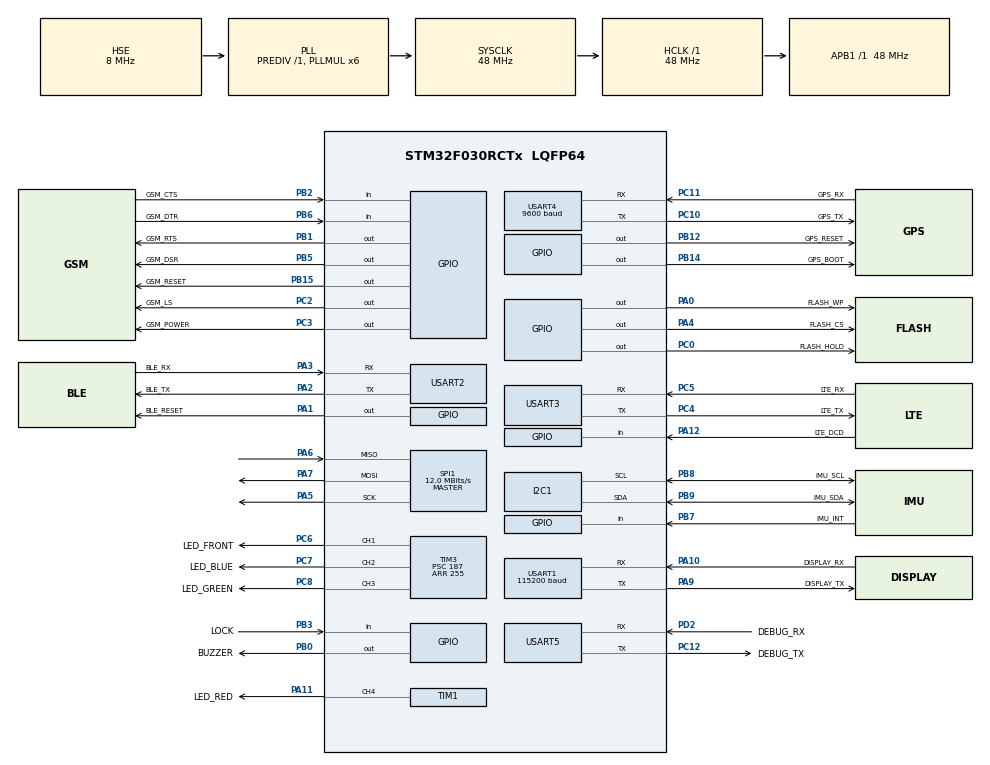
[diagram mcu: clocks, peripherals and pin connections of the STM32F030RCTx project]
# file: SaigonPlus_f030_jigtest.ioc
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Dma.Request0=USART2_RX
Dma.Request1=USART3_RX
Dma.Request2=USART4_RX
Dma.USART2_RX.0.Direction=DMA_PERIPH_TO_MEMORY
Dma.USART2_RX.0.Instance=DMA1_Channel5
Dma.USART2_RX.0.MemDataAlignment=DMA_MDATAALIGN_BYTE
Dma.USART2_RX.0.MemInc=DMA_MINC_ENABLE
Dma.USART2_RX.0.Mode=DMA_NORMAL
Dma.USART2_RX.0.PeriphDataAlignment=DMA_PDATAALIGN_BYTE
Dma.USART2_RX.0.PeriphInc=DMA_PINC_DISABLE
Dma.USART2_RX.0.Priority=DMA_PRIORITY_LOW
Dma.USART3_RX.1.Direction=DMA_PERIPH_TO_MEMORY
Dma.USART3_RX.1.Instance=DMA1_Channel1
Dma.USART3_RX.1.MemDataAlignment=DMA_MDATAALIGN_BYTE
Dma.USART3_RX.1.MemInc=DMA_MINC_ENABLE
Dma.USART3_RX.1.Mode=DMA_NORMAL
Dma.USART3_RX.1.PeriphDataAlignment=DMA_PDATAALIGN_BYTE
Dma.USART3_RX.1.PeriphInc=DMA_PINC_DISABLE
Dma.USART3_RX.1.Priority=DMA_PRIORITY_LOW
Dma.USART4_RX.2.Direction=DMA_PERIPH_TO_MEMORY
Dma.USART4_RX.2.Instance=DMA1_Channel3
Dma.USART4_RX.2.MemDataAlignment=DMA_MDATAALIGN_BYTE
Dma.USART4_RX.2.MemInc=DMA_MINC_ENABLE
Dma.USART4_RX.2.Mode=DMA_NORMAL
Dma.USART4_RX.2.PeriphDataAlignment=DMA_PDATAALIGN_BYTE
Dma.USART4_RX.2.PeriphInc=DMA_PINC_DISABLE
Dma.USART4_RX.2.Priority=DMA_PRIORITY_LOW
FREERTOS.INCLUDE_uxTaskGetStackHighWaterMark=1
FREERTOS.Mutexes01=appResource,Static,appResourceControlBlock;debugMutex,Static,debugMutexControlBlock;buzzerMutex,Static,buzzerMutexControlBlock;flashMutex,Static,flashMutexControlBlock;lteRingbufMutex,Static,lteRingbufMutexControlBlock;jigtestMutex,Static,jigtestMutexControlBlock
FREERTOS.Queues01=mainMail,5,mail_t,0,Static,mainMailBuffer,mainMailControlBlock;lteMail,5,mail_t,0,Static,lteMailBuffer,lteMailControlBlock;mqttMail,5,mail_t,0,Static,mqttMailBuffer,mqttMailControlBlock;jigTestMail,5,jigtest_mail_t,0,Static,jigTestMailBuffer,jigTestMailControlBlock
FREERTOS.Tasks01=mainTask,24,512,StartMainTask,Default,NULL,Static,mainTaskBuffer,mainTaskControlBlock;lteTask,24,512,LteTaskStart,Default,NULL,Static,lteTaskBuffer,lteTaskControlBlock;mqttTask,24,512,MqttTaskStart,Default,NULL,Static,mqttTaskBuffer,mqttTaskControlBlock;jigtestTask,24,256,StartJigtestTask,Default,NULL,Static,jigtestTaskBuffer,jigtestTaskControlBlock
FREERTOS.configTOTAL_HEAP_SIZE=1024
FREERTOS.configUSE_NEWLIB_REENTRANT=1
FREERTOS.configUSE_TIMERS=1
IWDG.Prescaler=IWDG_PRESCALER_256
Mcu.Family=STM32F0
Mcu.Name=STM32F030RCTx
Mcu.Package=LQFP64
NVIC.DMA1_Channel1_IRQn=true\:3\:0\:false\:false\:true\:true\:false\:true
NVIC.DMA1_Channel2_3_IRQn=true\:3\:0\:false\:false\:true\:true\:false\:true
NVIC.DMA1_Channel4_5_IRQn=true\:3\:0\:false\:false\:true\:true\:false\:true
NVIC.I2C1_IRQn=true\:3\:0\:true\:false\:true\:true\:true\:true
NVIC.TIM17_IRQn=true\:0\:0\:false\:false\:true\:false\:false\:true
NVIC.TimeBase=TIM17_IRQn
NVIC.TimeBaseIP=TIM17
NVIC.USART1_IRQn=true\:3\:0\:false\:false\:true\:true\:true\:true
NVIC.USART2_IRQn=true\:3\:0\:false\:false\:true\:true\:true\:true
NVIC.USART3_6_IRQn=true\:3\:0\:false\:false\:true\:true\:true\:true
PA0.GPIO_Label=FLASH_WP
PA0.PinState=GPIO_PIN_SET
PA0.Signal=GPIO_Output
PA1.GPIO_Label=BLE_RESET
PA1.PinState=GPIO_PIN_SET
PA1.Signal=GPIO_Output
PA10.GPIO_Label=DISPLAY_RX
PA10.Mode=Asynchronous
PA10.Signal=USART1_RX
PA11.GPIO_Label=LED_RED
PA11.Signal=S_TIM1_CH4
PA12.GPIO_Label=LTE_DCD
PA12.Signal=GPIO_Input
PA13.Mode=Serial_Wire
PA13.Signal=SYS_SWDIO
PA14.Mode=Serial_Wire
PA14.Signal=SYS_SWCLK
PA2.GPIO_Label=BLE_TX
PA2.Mode=Asynchronous
PA2.Signal=USART2_TX
PA3.GPIO_Label=BLE_RX
PA3.Mode=Asynchronous
PA3.Signal=USART2_RX
PA4.GPIO_Label=FLASH_CS
PA4.GPIO_Speed=GPIO_SPEED_FREQ_MEDIUM
PA4.PinState=GPIO_PIN_SET
PA4.Signal=GPIO_Output
PA5.Mode=Full_Duplex_Master
PA5.Signal=SPI1_SCK
PA6.Mode=Full_Duplex_Master
PA6.Signal=SPI1_MISO
PA7.Mode=Full_Duplex_Master
PA7.Signal=SPI1_MOSI
PA9.GPIO_Label=DISPLAY_TX
PA9.Mode=Asynchronous
PA9.Signal=USART1_TX
PB0.GPIO_Label=BUZZER
PB0.Signal=GPIO_Output
PB1.GPIO_Label=GSM_RTS
PB1.Signal=GPIO_Output
PB12.GPIO_Label=GPS_RESET
PB12.PinState=GPIO_PIN_SET
PB12.Signal=GPIO_Output
PB14.GPIO_Label=GPS_BOOT
PB14.PinState=GPIO_PIN_SET
PB14.Signal=GPIO_Output
PB15.GPIO_Label=GSM_RESET
PB15.PinState=GPIO_PIN_RESET
PB15.Signal=GPIO_Output
PB2.GPIO_Label=GSM_CTS
PB2.Signal=GPIO_Input
PB3.GPIO_Label=LOCK
PB3.GPIO_PuPd=GPIO_PULLUP
PB3.Signal=GPIO_Input
PB5.GPIO_Label=GSM_DSR
PB5.Signal=GPIO_Output
PB6.GPIO_Label=GSM_DTR
PB6.Signal=GPIO_Input
PB7.GPIO_Label=IMU_INT
PB7.Signal=GPIO_Input
PB8.GPIO_Label=IMU_SCL
PB8.GPIO_Pu=GPIO_PULLUP
PB8.Mode=I2C
PB8.Signal=I2C1_SCL
PB9.GPIO_Label=IMU_SDA
PB9.GPIO_Pu=GPIO_PULLUP
PB9.Mode=I2C
PB9.Signal=I2C1_SDA
PC0.GPIO_Label=FLASH_HOLD
PC0.PinState=GPIO_PIN_SET
PC0.Signal=GPIO_Output
PC10.GPIO_Label=GPS_TX
PC10.Mode=Asynchronous
PC10.Signal=USART4_TX
PC11.GPIO_Label=GPS_RX
PC11.Mode=Asynchronous
PC11.Signal=USART4_RX
PC12.GPIO_Label=DEBUG_TX
PC12.Mode=Asynchronous
PC12.Signal=USART5_TX
PC14OSC32_IN.Mode=LSE-External-Oscillator
PC14OSC32_IN.Signal=RCC_OSC32_IN
PC15OSC32_OUT.Mode=LSE-External-Oscillator
PC15OSC32_OUT.Signal=RCC_OSC32_OUT
PC2.GPIO_Label=GSM_LS
PC2.Signal=GPIO_Output
PC3.GPIO_Label=GSM_POWER
PC3.PinState=GPIO_PIN_RESET
PC3.Signal=GPIO_Output
PC4.GPIO_Label=LTE_TX
PC4.Mode=Asynchronous
PC4.Signal=USART3_TX
PC5.GPIO_Label=LTE_RX
PC5.Mode=Asynchronous
PC5.Signal=USART3_RX
PC6.GPIO_Label=LED_FRONT
PC6.Signal=S_TIM3_CH1
PC7.GPIO_Label=LED_BLUE
PC7.Signal=S_TIM3_CH2
PC8.GPIO_Label=LED_GREEN
PC8.Signal=S_TIM3_CH3
PD2.GPIO_Label=DEBUG_RX
PD2.Mode=Asynchronous
PD2.Signal=USART5_RX
PF0-OSC_IN.Mode=HSE-External-Oscillator
PF0-OSC_IN.Signal=RCC_OSC_IN
PF1-OSC_OUT.Mode=HSE-External-Oscillator
PF1-OSC_OUT.Signal=RCC_OSC_OUT
ProjectManager.HeapSize=0x200
ProjectManager.StackSize=0x400
ProjectManager.TargetToolchain=STM32CubeIDE
RCC.AHBFreq_Value=48000000
RCC.APB1Freq_Value=48000000
RCC.APB1TimFreq_Value=48000000
RCC.HCLKFreq_Value=48000000
RCC.PLLMUL=RCC_PLL_MUL6
RCC.PLLSourceVirtual=RCC_PLLSOURCE_HSE
RCC.SYSCLKFreq_VALUE=48000000
RCC.SYSCLKSource=RCC_SYSCLKSOURCE_PLLCLK
SH.S_TIM1_CH4.0=TIM1_CH4,PWM Generation4 CH4
SH.S_TIM3_CH1.0=TIM3_CH1,PWM Generation1 CH1
SH.S_TIM3_CH2.0=TIM3_CH2,PWM Generation2 CH2
SH.S_TIM3_CH3.0=TIM3_CH3,PWM Generation3 CH3
SPI1.BaudRatePrescaler=SPI_BAUDRATEPRESCALER_4
SPI1.CalculateBaudRate=12.0 MBits/s
SPI1.DataSize=SPI_DATASIZE_8BIT
SPI1.Direction=SPI_DIRECTION_2LINES
SPI1.Mode=SPI_MODE_MASTER
SPI1.VirtualType=VM_MASTER
TIM1.Channel-PWM\ Generation4\ CH4=TIM_CHANNEL_4
TIM1.Period=255
TIM1.Prescaler=187
TIM3.Channel-PWM\ Generation1\ CH1=TIM_CHANNEL_1
TIM3.Channel-PWM\ Generation2\ CH2=TIM_CHANNEL_2
TIM3.Channel-PWM\ Generation3\ CH3=TIM_CHANNEL_3
TIM3.Period=255
TIM3.Prescaler=187
USART1.BaudRate=115200
USART1.VirtualMode-Asynchronous=VM_ASYNC
USART2.VirtualMode-Asynchronous=VM_ASYNC
USART3.VirtualMode-Asynchronous=VM_ASYNC
USART4.BaudRate=9600
USART4.VirtualMode-Asynchronous=VM_ASYNC
USART5.VirtualMode-Asynchronous=VM_ASYNC
VP_CRC_VS_CRC.Mode=CRC_Activate
VP_FREERTOS_VS_CMSIS_V2.Mode=CMSIS_V2
VP_IWDG_VS_IWDG.Mode=IWDG_Activate
VP_RTC_VS_RTC_Activate.Mode=RTC_Enabled
VP_SYS_VS_tim17.Mode=TIM17
board=custom

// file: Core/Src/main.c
/* USER CODE BEGIN Header */
/**
  ******************************************************************************
  * @file           : main.c
  * @brief          : Main program body
  ******************************************************************************
  * @attention
  *
  * <h2><center>&copy; Copyright (c) 2021 STMicroelectronics.
  * All rights reserved.</center></h2>
  *
  * This software component is licensed by ST under BSD 3-Clause license,
  * the "License"; You may not use this file except in compliance with the
  * License. You may obtain a copy of the License at:
  *                        opensource.org/licenses/BSD-3-Clause
  *
  ******************************************************************************
  */
/* USER CODE END Header */
#include "main.h"
#include "cmsis_os.h"
#include "crc.h"
#include "dma.h"
#include "i2c.h"
#include "iwdg.h"
#include "rtc.h"
#include "spi.h"
#include "tim.h"
#include "usart.h"
#include "gpio.h"

void SystemClock_Config(void);
void MX_FREERTOS_Init(void);

int main(void)
{

  /* MCU Configuration--------------------------------------------------------*/

  /* Reset of all peripherals, Initializes the Flash interface and the Systick. */
  HAL_Init();

  /* Configure the system clock */
  SystemClock_Config();

  /* Initialize all configured peripherals */
  MX_GPIO_Init();
  MX_DMA_Init();
  MX_USART3_UART_Init();
  MX_USART5_UART_Init();
  MX_USART4_UART_Init();
  MX_SPI1_Init();
  MX_USART2_UART_Init();
  MX_USART1_UART_Init();
  MX_I2C1_Init();
  MX_IWDG_Init();
  MX_RTC_Init();
  MX_TIM1_Init();
  MX_TIM3_Init();
  MX_CRC_Init();

  /* Init scheduler */
  osKernelInitialize();  /* Call init function for freertos objects (in freertos.c) */
  MX_FREERTOS_Init();
  /* Start scheduler */
  osKernelStart();

  /* We should never get here as control is now taken by the scheduler */
  /* Infinite loop */
  while (1)
  {

  }
}

void SystemClock_Config(void)
{
  RCC_OscInitTypeDef RCC_OscInitStruct = {0};
  RCC_ClkInitTypeDef RCC_ClkInitStruct = {0};
  RCC_PeriphCLKInitTypeDef PeriphClkInit = {0};

  /** Initializes the RCC Oscillators according to the specified parameters
  * in the RCC_OscInitTypeDef structure.
  */
  RCC_OscInitStruct.OscillatorType = RCC_OSCILLATORTYPE_HSI|RCC_OSCILLATORTYPE_LSI
                              |RCC_OSCILLATORTYPE_HSE;
  RCC_OscInitStruct.HSEState = RCC_HSE_ON;
  RCC_OscInitStruct.HSIState = RCC_HSI_ON;
  RCC_OscInitStruct.HSICalibrationValue = RCC_HSICALIBRATION_DEFAULT;
  RCC_OscInitStruct.LSIState = RCC_LSI_ON;
  RCC_OscInitStruct.PLL.PLLState = RCC_PLL_ON;
  RCC_OscInitStruct.PLL.PLLSource = RCC_PLLSOURCE_HSE;
  RCC_OscInitStruct.PLL.PLLMUL = RCC_PLL_MUL6;
  RCC_OscInitStruct.PLL.PREDIV = RCC_PREDIV_DIV1;
  if (HAL_RCC_OscConfig(&RCC_OscInitStruct) != HAL_OK)
  {
    Error_Handler();
  }
  /** Initializes the CPU, AHB and APB buses clocks
  */
  RCC_ClkInitStruct.ClockType = RCC_CLOCKTYPE_HCLK|RCC_CLOCKTYPE_SYSCLK
                              |RCC_CLOCKTYPE_PCLK1;
  RCC_ClkInitStruct.SYSCLKSource = RCC_SYSCLKSOURCE_PLLCLK;
  RCC_ClkInitStruct.AHBCLKDivider = RCC_SYSCLK_DIV1;
  RCC_ClkInitStruct.APB1CLKDivider = RCC_HCLK_DIV1;

  if (HAL_RCC_ClockConfig(&RCC_ClkInitStruct, FLASH_LATENCY_1) != HAL_OK)
  {
    Error_Handler();
  }
  PeriphClkInit.PeriphClockSelection = RCC_PERIPHCLK_USART1|RCC_PERIPHCLK_I2C1
                              |RCC_PERIPHCLK_RTC;
  PeriphClkInit.Usart1ClockSelection = RCC_USART1CLKSOURCE_PCLK1;
  PeriphClkInit.I2c1ClockSelection = RCC_I2C1CLKSOURCE_HSI;
  PeriphClkInit.RTCClockSelection = RCC_RTCCLKSOURCE_LSI;
  if (HAL_RCCEx_PeriphCLKConfig(&PeriphClkInit) != HAL_OK)
  {
    Error_Handler();
  }
}

void HAL_TIM_PeriodElapsedCallback(TIM_HandleTypeDef *htim)
{
  if (htim->Instance == TIM17) {
    HAL_IncTick();
  }
}

void Error_Handler(void)
{
  __disable_irq();
  while (1)
  {
  }
}

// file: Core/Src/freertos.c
/* USER CODE BEGIN Header */
/**
  ******************************************************************************
  * File Name          : freertos.c
  * Description        : Code for freertos applications
  ******************************************************************************
  * @attention
  *
  * <h2><center>&copy; Copyright (c) 2021 STMicroelectronics.
  * All rights reserved.</center></h2>
  *
  * This software component is licensed by ST under Ultimate Liberty license
  * SLA0044, the "License"; You may not use this file except in compliance with
  * the License. You may obtain a copy of the License at:
  *                             www.st.com/SLA0044
  *
  ******************************************************************************
  */
/* USER CODE END Header */

#include "FreeRTOS.h"
#include "task.h"
#include "main.h"
#include "cmsis_os.h"

typedef StaticTask_t osStaticThreadDef_t;
typedef StaticQueue_t osStaticMessageQDef_t;
typedef StaticSemaphore_t osStaticMutexDef_t;

/* Definitions for mainTask */
osThreadId_t mainTaskHandle;
uint32_t mainTaskBuffer[ 512 ];
osStaticThreadDef_t mainTaskControlBlock;
const osThreadAttr_t mainTask_attributes = {
  .name = "mainTask",
  .cb_mem = &mainTaskControlBlock,
  .cb_size = sizeof(mainTaskControlBlock),
  .stack_mem = &mainTaskBuffer[0],
  .stack_size = sizeof(mainTaskBuffer),
  .priority = (osPriority_t) osPriorityNormal,
};
/* Definitions for lteTask */
osThreadId_t lteTaskHandle;
uint32_t lteTaskBuffer[ 512 ];
osStaticThreadDef_t lteTaskControlBlock;
const osThreadAttr_t lteTask_attributes = {
  .name = "lteTask",
  .cb_mem = &lteTaskControlBlock,
  .cb_size = sizeof(lteTaskControlBlock),
  .stack_mem = &lteTaskBuffer[0],
  .stack_size = sizeof(lteTaskBuffer),
  .priority = (osPriority_t) osPriorityNormal,
};
/* Definitions for mqttTask */
osThreadId_t mqttTaskHandle;
uint32_t mqttTaskBuffer[ 512 ];
osStaticThreadDef_t mqttTaskControlBlock;
const osThreadAttr_t mqttTask_attributes = {
  .name = "mqttTask",
  .cb_mem = &mqttTaskControlBlock,
  .cb_size = sizeof(mqttTaskControlBlock),
  .stack_mem = &mqttTaskBuffer[0],
  .stack_size = sizeof(mqttTaskBuffer),
  .priority = (osPriority_t) osPriorityNormal,
};
/* Definitions for jigtestTask */
osThreadId_t jigtestTaskHandle;
uint32_t jigtestTaskBuffer[ 256 ];
osStaticThreadDef_t jigtestTaskControlBlock;
const osThreadAttr_t jigtestTask_attributes = {
  .name = "jigtestTask",
  .cb_mem = &jigtestTaskControlBlock,
  .cb_size = sizeof(jigtestTaskControlBlock),
  .stack_mem = &jigtestTaskBuffer[0],
  .stack_size = sizeof(jigtestTaskBuffer),
  .priority = (osPriority_t) osPriorityNormal,
};
/* Definitions for mainMail */
osMessageQueueId_t mainMailHandle;
uint8_t mainMailBuffer[ 5 * sizeof( mail_t ) ];
osStaticMessageQDef_t mainMailControlBlock;
const osMessageQueueAttr_t mainMail_attributes = {
  .name = "mainMail",
  .cb_mem = &mainMailControlBlock,
  .cb_size = sizeof(mainMailControlBlock),
  .mq_mem = &mainMailBuffer,
  .mq_size = sizeof(mainMailBuffer)
};
/* Definitions for lteMail */
osMessageQueueId_t lteMailHandle;
uint8_t lteMailBuffer[ 5 * sizeof( mail_t ) ];
osStaticMessageQDef_t lteMailControlBlock;
const osMessageQueueAttr_t lteMail_attributes = {
  .name = "lteMail",
  .cb_mem = &lteMailControlBlock,
  .cb_size = sizeof(lteMailControlBlock),
  .mq_mem = &lteMailBuffer,
  .mq_size = sizeof(lteMailBuffer)
};
/* Definitions for mqttMail */
osMessageQueueId_t mqttMailHandle;
uint8_t mqttMailBuffer[ 5 * sizeof( mail_t ) ];
osStaticMessageQDef_t mqttMailControlBlock;
const osMessageQueueAttr_t mqttMail_attributes = {
  .name = "mqttMail",
  .cb_mem = &mqttMailControlBlock,
  .cb_size = sizeof(mqttMailControlBlock),
  .mq_mem = &mqttMailBuffer,
  .mq_size = sizeof(mqttMailBuffer)
};
/* Definitions for jigTestMail */
osMessageQueueId_t jigTestMailHandle;
uint8_t jigTestMailBuffer[ 5 * sizeof( jigtest_mail_t ) ];
osStaticMessageQDef_t jigTestMailControlBlock;
const osMessageQueueAttr_t jigTestMail_attributes = {
  .name = "jigTestMail",
  .cb_mem = &jigTestMailControlBlock,
  .cb_size = sizeof(jigTestMailControlBlock),
  .mq_mem = &jigTestMailBuffer,
  .mq_size = sizeof(jigTestMailBuffer)
};
/* Definitions for appResource */
osMutexId_t appResourceHandle;
osStaticMutexDef_t appResourceControlBlock;
const osMutexAttr_t appResource_attributes = {
  .name = "appResource",
  .cb_mem = &appResourceControlBlock,
  .cb_size = sizeof(appResourceControlBlock),
};
/* Definitions for debugMutex */
osMutexId_t debugMutexHandle;
osStaticMutexDef_t debugMutexControlBlock;
const osMutexAttr_t debugMutex_attributes = {
  .name = "debugMutex",
  .cb_mem = &debugMutexControlBlock,
  .cb_size = sizeof(debugMutexControlBlock),
};
/* Definitions for buzzerMutex */
osMutexId_t buzzerMutexHandle;
osStaticMutexDef_t buzzerMutexControlBlock;
const osMutexAttr_t buzzerMutex_attributes = {
  .name = "buzzerMutex",
  .cb_mem = &buzzerMutexControlBlock,
  .cb_size = sizeof(buzzerMutexControlBlock),
};
/* Definitions for flashMutex */
osMutexId_t flashMutexHandle;
osStaticMutexDef_t flashMutexControlBlock;
const osMutexAttr_t flashMutex_attributes = {
  .name = "flashMutex",
  .cb_mem = &flashMutexControlBlock,
  .cb_size = sizeof(flashMutexControlBlock),
};
/* Definitions for lteRingbufMutex */
osMutexId_t lteRingbufMutexHandle;
osStaticMutexDef_t lteRingbufMutexControlBlock;
const osMutexAttr_t lteRingbufMutex_attributes = {
  .name = "lteRingbufMutex",
  .cb_mem = &lteRingbufMutexControlBlock,
  .cb_size = sizeof(lteRingbufMutexControlBlock),
};
/* Definitions for jigtestMutex */
osMutexId_t jigtestMutexHandle;
osStaticMutexDef_t jigtestMutexControlBlock;
const osMutexAttr_t jigtestMutex_attributes = {
  .name = "jigtestMutex",
  .cb_mem = &jigtestMutexControlBlock,
  .cb_size = sizeof(jigtestMutexControlBlock),
};

void StartMainTask(void *argument);
void LteTaskStart(void *argument);
void MqttTaskStart(void *argument);
void StartJigtestTask(void *argument);

void MX_FREERTOS_Init(void); /* (MISRA C 2004 rule 8.1) */

void MX_FREERTOS_Init(void) {
  /* Create the mutex(es) */
  /* creation of appResource */
  appResourceHandle = osMutexNew(&appResource_attributes);

  /* creation of debugMutex */
  debugMutexHandle = osMutexNew(&debugMutex_attributes);

  /* creation of buzzerMutex */
  buzzerMutexHandle = osMutexNew(&buzzerMutex_attributes);

  /* creation of flashMutex */
  flashMutexHandle = osMutexNew(&flashMutex_attributes);

  /* creation of lteRingbufMutex */
  lteRingbufMutexHandle = osMutexNew(&lteRingbufMutex_attributes);

  /* creation of jigtestMutex */
  jigtestMutexHandle = osMutexNew(&jigtestMutex_attributes);

  /* Create the queue(s) */
  /* creation of mainMail */
  mainMailHandle = osMessageQueueNew (5, sizeof(mail_t), &mainMail_attributes);

  /* creation of lteMail */
  lteMailHandle = osMessageQueueNew (5, sizeof(mail_t), &lteMail_attributes);

  /* creation of mqttMail */
  mqttMailHandle = osMessageQueueNew (5, sizeof(mail_t), &mqttMail_attributes);

  /* creation of jigTestMail */
  jigTestMailHandle = osMessageQueueNew (5, sizeof(jigtest_mail_t), &jigTestMail_attributes);

  /* Create the thread(s) */
  /* creation of mainTask */
  mainTaskHandle = osThreadNew(StartMainTask, NULL, &mainTask_attributes);

  /* creation of lteTask */
  lteTaskHandle = osThreadNew(LteTaskStart, NULL, &lteTask_attributes);

  /* creation of mqttTask */
  mqttTaskHandle = osThreadNew(MqttTaskStart, NULL, &mqttTask_attributes);

  /* creation of jigtestTask */
  jigtestTaskHandle = osThreadNew(StartJigtestTask, NULL, &jigtestTask_attributes);

}

void StartMainTask(void *argument)
{
  /* USER CODE BEGIN StartMainTask */
  /* Infinite loop */
	app_main();
  for(;;)
  {
    osDelay(5);
  }
  /* USER CODE END StartMainTask */
}

void LteTaskStart(void *argument)
{
  /* USER CODE BEGIN LteTaskStart */
  /* Infinite loop */
	lte_task();
  for(;;)
  {
    osDelay(5);
  }
  /* USER CODE END LteTaskStart */
}

void MqttTaskStart(void *argument)
{
  /* USER CODE BEGIN MqttTaskStart */
  /* Infinite loop */
	app_mqtt();
  for(;;)
  {
    osDelay(5);
  }
  /* USER CODE END MqttTaskStart */
}

void StartJigtestTask(void *argument)
{
  for(;;)
  {
    osDelay(1);
  }
}
